# PIC32MZ1024EFE064 register map
Vendor: Microchip
Registers are 32-bit, read-write, reset 0x0 unless marked. A register's access mark holds for its fields unless they carry their own. Addresses are absolute, and some are shared; only a register's first bit layout is shown; [hi:lo] are bit positions.

## ICAP2
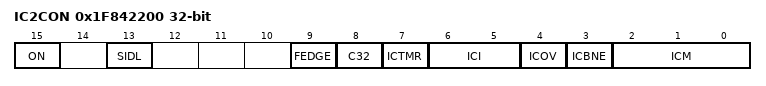
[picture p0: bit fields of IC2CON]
0x1F842200 IC2CON
  [15] ON, [13] SIDL, [9] FEDGE, [8] C32, [7] ICTMR, [6:5] ICI, [4] ICOV ro, [3] ICBNE ro, [2:0] ICM
0x1F842210 IC2BUF ro reset not defined — (power-on value xxxxxxxxxxxxxxxxxxxxxxxxxxxxxxxx)

## ICAP3
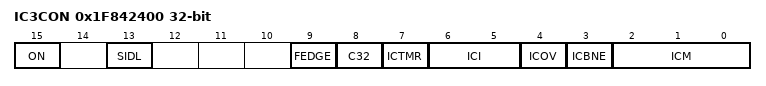
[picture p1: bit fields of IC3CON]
0x1F842400 IC3CON
  [15] ON, [13] SIDL, [9] FEDGE, [8] C32, [7] ICTMR, [6:5] ICI, [4] ICOV ro, [3] ICBNE ro, [2:0] ICM
0x1F842410 IC3BUF ro reset not defined — (power-on value xxxxxxxxxxxxxxxxxxxxxxxxxxxxxxxx)

## ICAP4
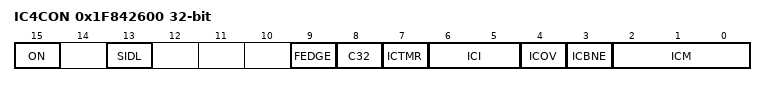
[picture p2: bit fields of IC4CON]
0x1F842600 IC4CON
  [15] ON, [13] SIDL, [9] FEDGE, [8] C32, [7] ICTMR, [6:5] ICI, [4] ICOV ro, [3] ICBNE ro, [2:0] ICM
0x1F842610 IC4BUF ro reset not defined — (power-on value xxxxxxxxxxxxxxxxxxxxxxxxxxxxxxxx)

## ICAP5
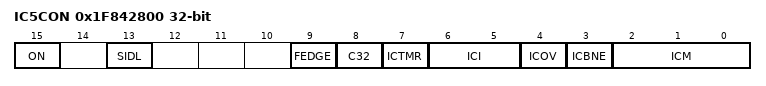
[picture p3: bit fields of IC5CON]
0x1F842800 IC5CON
  [15] ON, [13] SIDL, [9] FEDGE, [8] C32, [7] ICTMR, [6:5] ICI, [4] ICOV ro, [3] ICBNE ro, [2:0] ICM
0x1F842810 IC5BUF ro reset not defined — (power-on value xxxxxxxxxxxxxxxxxxxxxxxxxxxxxxxx)

## ICAP6
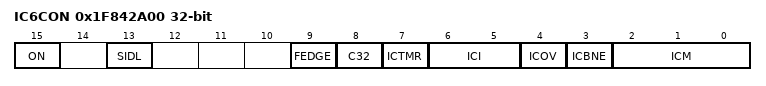
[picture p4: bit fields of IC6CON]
0x1F842A00 IC6CON
  [15] ON, [13] SIDL, [9] FEDGE, [8] C32, [7] ICTMR, [6:5] ICI, [4] ICOV ro, [3] ICBNE ro, [2:0] ICM
0x1F842A10 IC6BUF ro reset not defined — (power-on value xxxxxxxxxxxxxxxxxxxxxxxxxxxxxxxx)

## ICAP7
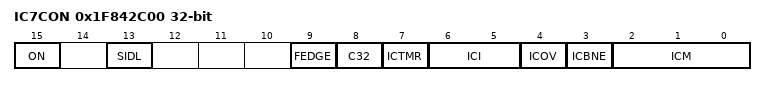
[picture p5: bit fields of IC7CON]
0x1F842C00 IC7CON
  [15] ON, [13] SIDL, [9] FEDGE, [8] C32, [7] ICTMR, [6:5] ICI, [4] ICOV ro, [3] ICBNE ro, [2:0] ICM
0x1F842C10 IC7BUF ro reset not defined — (power-on value xxxxxxxxxxxxxxxxxxxxxxxxxxxxxxxx)

## ICAP8
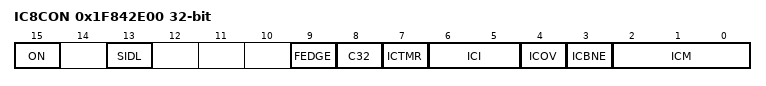
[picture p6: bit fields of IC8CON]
0x1F842E00 IC8CON
  [15] ON, [13] SIDL, [9] FEDGE, [8] C32, [7] ICTMR, [6:5] ICI, [4] ICOV ro, [3] ICBNE ro, [2:0] ICM
0x1F842E10 IC8BUF ro reset not defined — (power-on value xxxxxxxxxxxxxxxxxxxxxxxxxxxxxxxx)

## ICAP9
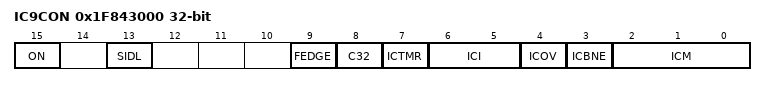
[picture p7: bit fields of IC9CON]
0x1F843000 IC9CON
  [15] ON, [13] SIDL, [9] FEDGE, [8] C32, [7] ICTMR, [6:5] ICI, [4] ICOV ro, [3] ICBNE ro, [2:0] ICM
0x1F843010 IC9BUF ro reset not defined — (power-on value xxxxxxxxxxxxxxxxxxxxxxxxxxxxxxxx)

## OCMP1
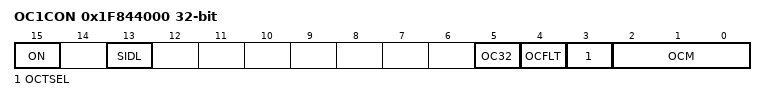
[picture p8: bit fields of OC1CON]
0x1F844000 OC1CON
  [15] ON, [13] SIDL, [5] OC32, [4] OCFLT ro, [3] OCTSEL, [2:0] OCM
0x1F844010 OC1R reset not defined — (power-on value xxxxxxxxxxxxxxxxxxxxxxxxxxxxxxxx)
0x1F844020 OC1RS reset not defined — (power-on value xxxxxxxxxxxxxxxxxxxxxxxxxxxxxxxx)

## OCMP2
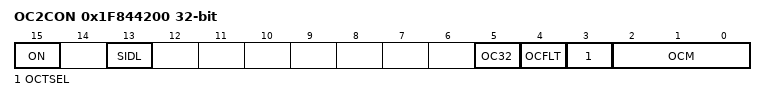
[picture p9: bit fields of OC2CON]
0x1F844200 OC2CON
  [15] ON, [13] SIDL, [5] OC32, [4] OCFLT ro, [3] OCTSEL, [2:0] OCM
0x1F844210 OC2R reset not defined — (power-on value xxxxxxxxxxxxxxxxxxxxxxxxxxxxxxxx)
0x1F844220 OC2RS reset not defined — (power-on value xxxxxxxxxxxxxxxxxxxxxxxxxxxxxxxx)

## OCMP3
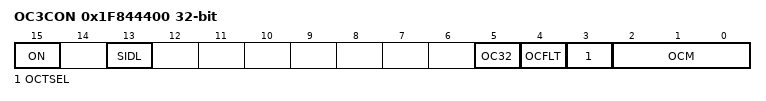
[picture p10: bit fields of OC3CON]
0x1F844400 OC3CON
  [15] ON, [13] SIDL, [5] OC32, [4] OCFLT ro, [3] OCTSEL, [2:0] OCM
0x1F844410 OC3R reset not defined — (power-on value xxxxxxxxxxxxxxxxxxxxxxxxxxxxxxxx)
0x1F844420 OC3RS reset not defined — (power-on value xxxxxxxxxxxxxxxxxxxxxxxxxxxxxxxx)

## OCMP4
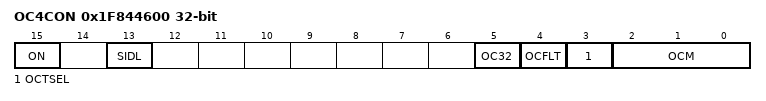
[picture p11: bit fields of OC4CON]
0x1F844600 OC4CON
  [15] ON, [13] SIDL, [5] OC32, [4] OCFLT ro, [3] OCTSEL, [2:0] OCM
0x1F844610 OC4R reset not defined — (power-on value xxxxxxxxxxxxxxxxxxxxxxxxxxxxxxxx)
0x1F844620 OC4RS reset not defined — (power-on value xxxxxxxxxxxxxxxxxxxxxxxxxxxxxxxx)

## OCMP5
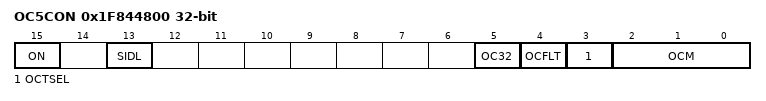
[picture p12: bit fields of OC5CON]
0x1F844800 OC5CON
  [15] ON, [13] SIDL, [5] OC32, [4] OCFLT ro, [3] OCTSEL, [2:0] OCM
0x1F844810 OC5R reset not defined — (power-on value xxxxxxxxxxxxxxxxxxxxxxxxxxxxxxxx)
0x1F844820 OC5RS reset not defined — (power-on value xxxxxxxxxxxxxxxxxxxxxxxxxxxxxxxx)

## OCMP6
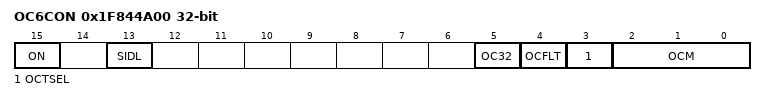
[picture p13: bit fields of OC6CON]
0x1F844A00 OC6CON
  [15] ON, [13] SIDL, [5] OC32, [4] OCFLT ro, [3] OCTSEL, [2:0] OCM
0x1F844A10 OC6R reset not defined — (power-on value xxxxxxxxxxxxxxxxxxxxxxxxxxxxxxxx)
0x1F844A20 OC6RS reset not defined — (power-on value xxxxxxxxxxxxxxxxxxxxxxxxxxxxxxxx)
